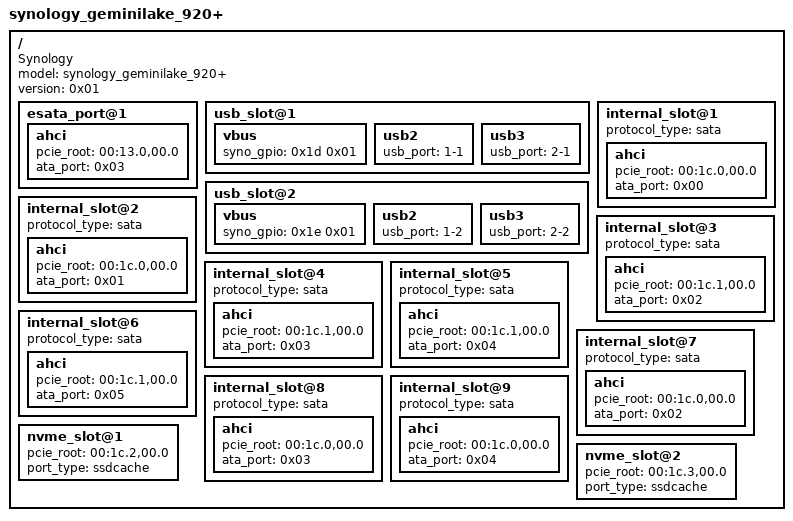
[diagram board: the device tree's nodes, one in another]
/dts-v1/;

/ {
	compatible = "Synology";
	model = "synology_geminilake_920+";
	version = <0x01>;
	
	esata_port@1 {

		ahci {
			pcie_root = "00:13.0,00.0";
			ata_port = <0x03>;
		};
	};

	usb_slot@1 {

		vbus {
			syno_gpio = <0x1d 0x01>;
		};

		usb2 {
			usb_port = "1-1";
		};

		usb3 {
			usb_port = "2-1";
		};
	};

	usb_slot@2 {

		vbus {
			syno_gpio = <0x1e 0x01>;
		};

		usb2 {
			usb_port = "1-2";
		};

		usb3 {
			usb_port = "2-2";
		};
	};

	internal_slot@1 {
		protocol_type = "sata";
		ahci {
			pcie_root = "00:1c.0,00.0";
			ata_port = <0x00>;
		};
	};

	internal_slot@2 {
		protocol_type = "sata";
		ahci {
			pcie_root = "00:1c.0,00.0";
			ata_port = <0x01>;
		};
	};

	internal_slot@3 {
		protocol_type = "sata";
		ahci {
			pcie_root = "00:1c.1,00.0";
			ata_port = <0x02>;
		};
	};

	internal_slot@4 {
		protocol_type = "sata";
		ahci {
			pcie_root = "00:1c.1,00.0";
			ata_port = <0x03>;
		};
	};

	internal_slot@5 {
		protocol_type = "sata";
		ahci {
			pcie_root = "00:1c.1,00.0";
			ata_port = <0x04>;
		};
	};

	internal_slot@6 {
		protocol_type = "sata";
		ahci {
			pcie_root = "00:1c.1,00.0";
			ata_port = <0x05>;
		};
	};

	internal_slot@7 {
		protocol_type = "sata";
		ahci {
			pcie_root = "00:1c.0,00.0";
			ata_port = <0x02>;
		};
	};
	
	internal_slot@8 {
		protocol_type = "sata";
		ahci {
			pcie_root = "00:1c.0,00.0";
			ata_port = <0x03>;
		};
	};
	
	internal_slot@9 {
		protocol_type = "sata";
		ahci {
			pcie_root = "00:1c.0,00.0";
			ata_port = <0x04>;
		};
	};

	nvme_slot@1 {
		pcie_root = "00:1c.2,00.0";
		port_type = "ssdcache";
	};

	nvme_slot@2 {
		pcie_root = "00:1c.3,00.0";
		port_type = "ssdcache";
	};
};
